# nrf54lm20a_enga_application register map
Vendor: Nordic Semiconductor; Series: nrf54l; File version: 1
CPU: CM33 r0p4, little endian, MPU, FPU, 3 interrupt priority bits, 270 interrupts, 4 SAU regions
Registers are 32-bit, read-write, reset 0x0 unless marked. A register's access mark holds for its fields unless they carry their own. Offsets are from the block's base; [hi:lo] are bit positions; lines under a group give offsets from that group; 'fields as' and 'values as' point back to an identical list.

## GLOBAL_CLOCK_NS — Clock management 0
Base 0x4010E000
Same registers: GLOBAL_CLOCK_S 0x5010E000
0x00 TASKS_XOSTART wo — Start crystal oscillator (HFXO)
  [0] TASKS_XOSTART
    1=Trigger task
0x04 TASKS_XOSTOP wo — Stop crystal oscillator (HFXO)
  [0] TASKS_XOSTOP
    1=Trigger task
0x08 TASKS_PLLSTART wo — Start PLL and keep it running, regardless of the automatic clock requests
  [0] TASKS_PLLSTART
    1=Trigger task
0x0C TASKS_PLLSTOP wo — Stop PLL
  [0] TASKS_PLLSTOP
    1=Trigger task
0x10 TASKS_LFCLKSTART wo — Start LFCLK source as selected in LFCLK.SRC
  [0] TASKS_LFCLKSTART
    1=Trigger task
0x14 TASKS_LFCLKSTOP wo — Stop LFCLK source
  [0] TASKS_LFCLKSTOP
    1=Trigger task
0x18 TASKS_CAL wo — Start calibration of LFRC oscillator
  [0] TASKS_CAL
    1=Trigger task
0x1C TASKS_XOTUNE wo — Request tuning for HFXO Request IDAC regulation for XOSC32M
  [0] TASKS_XOTUNE
    1=Trigger task
0x20 TASKS_XOTUNEABORT wo — Abort tuning for HFXO Abort IDAC regulation for XOSC32M. The latest IDAC code applied when ABORT is triggered will be used. Refer to DD: digip_1223
  [0] TASKS_XOTUNEABORT
    1=Trigger task
0x24 TASKS_XO24MSTART wo — Request HFXO to provide a crystal clock for PCLK24M
  [0] TASKS_XO24MSTART
    1=Trigger task
0x28 TASKS_XO24MSTOP wo — Stop request HFXO for PCLK24M. sWhen all requests for HFXO are stopped, HFXO will also stop.
  [0] TASKS_XO24MSTOP
    1=Trigger task
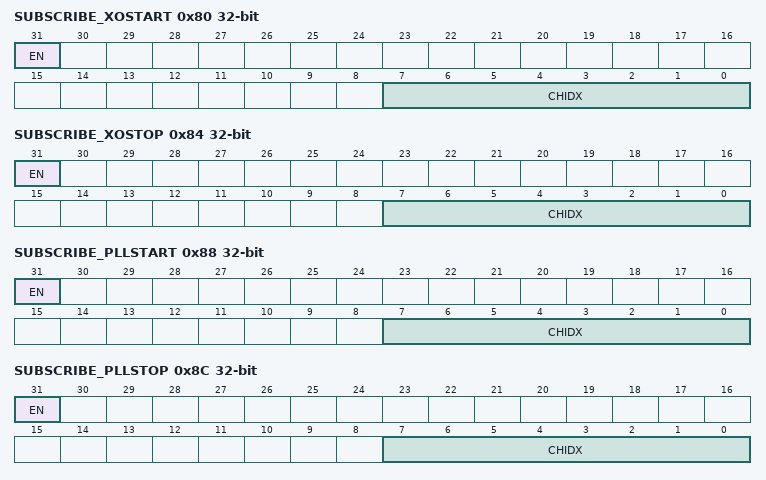
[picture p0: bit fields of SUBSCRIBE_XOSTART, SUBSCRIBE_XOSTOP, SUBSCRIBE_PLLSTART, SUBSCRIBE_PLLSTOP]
0x80 SUBSCRIBE_XOSTART — Subscribe configuration for task XOSTART
  [31] EN
    0=Disabled (Disable subscription); 1=Enabled (Enable subscription)
  [7:0] CHIDX — DPPI channel that task XOSTART will subscribe to
0x84 SUBSCRIBE_XOSTOP — Subscribe configuration for task XOSTOP
  [31] EN
    values as SUBSCRIBE_XOSTART.EN
  [7:0] CHIDX — DPPI channel that task XOSTOP will subscribe to
0x88 SUBSCRIBE_PLLSTART — Subscribe configuration for task PLLSTART
  [31] EN
    values as SUBSCRIBE_XOSTART.EN
  [7:0] CHIDX — DPPI channel that task PLLSTART will subscribe to
0x8C SUBSCRIBE_PLLSTOP — Subscribe configuration for task PLLSTOP
  [31] EN
    values as SUBSCRIBE_XOSTART.EN
  [7:0] CHIDX — DPPI channel that task PLLSTOP will subscribe to
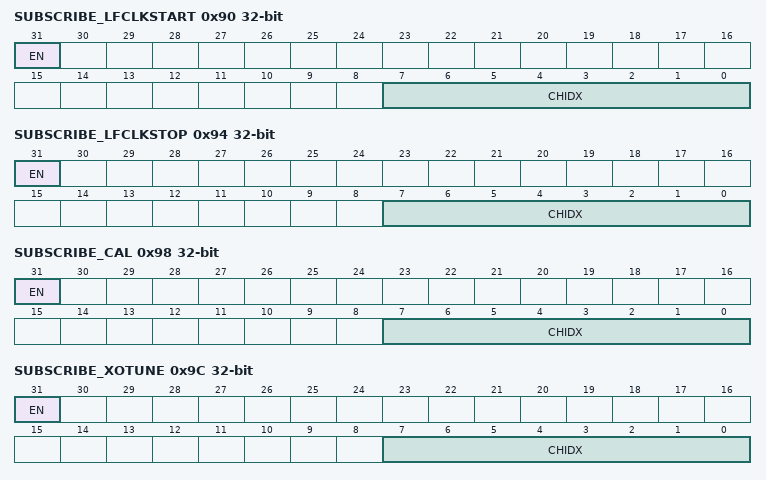
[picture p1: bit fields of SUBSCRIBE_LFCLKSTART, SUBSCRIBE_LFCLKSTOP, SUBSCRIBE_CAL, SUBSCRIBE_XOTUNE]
0x90 SUBSCRIBE_LFCLKSTART — Subscribe configuration for task LFCLKSTART
  [31] EN
    values as SUBSCRIBE_XOSTART.EN
  [7:0] CHIDX — DPPI channel that task LFCLKSTART will subscribe to
0x94 SUBSCRIBE_LFCLKSTOP — Subscribe configuration for task LFCLKSTOP
  [31] EN
    values as SUBSCRIBE_XOSTART.EN
  [7:0] CHIDX — DPPI channel that task LFCLKSTOP will subscribe to
0x98 SUBSCRIBE_CAL — Subscribe configuration for task CAL
  [31] EN
    values as SUBSCRIBE_XOSTART.EN
  [7:0] CHIDX — DPPI channel that task CAL will subscribe to
0x9C SUBSCRIBE_XOTUNE — Subscribe configuration for task XOTUNE
  [31] EN
    values as SUBSCRIBE_XOSTART.EN
  [7:0] CHIDX — DPPI channel that task XOTUNE will subscribe to
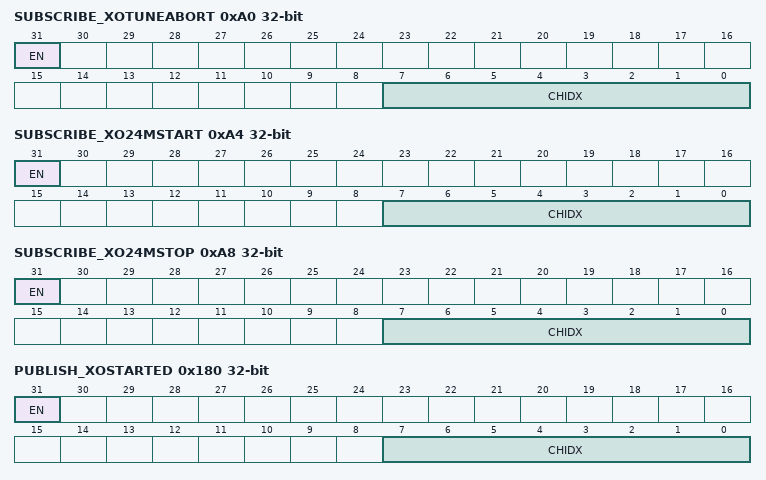
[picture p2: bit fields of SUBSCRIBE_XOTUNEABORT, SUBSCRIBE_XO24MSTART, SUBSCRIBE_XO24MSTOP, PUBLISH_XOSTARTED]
0xA0 SUBSCRIBE_XOTUNEABORT — Subscribe configuration for task XOTUNEABORT
  [31] EN
    values as SUBSCRIBE_XOSTART.EN
  [7:0] CHIDX — DPPI channel that task XOTUNEABORT will subscribe to
0xA4 SUBSCRIBE_XO24MSTART — Subscribe configuration for task XO24MSTART
  [31] EN
    values as SUBSCRIBE_XOSTART.EN
  [7:0] CHIDX — DPPI channel that task XO24MSTART will subscribe to
0xA8 SUBSCRIBE_XO24MSTOP — Subscribe configuration for task XO24MSTOP
  [31] EN
    values as SUBSCRIBE_XOSTART.EN
  [7:0] CHIDX — DPPI channel that task XO24MSTOP will subscribe to
0x100 EVENTS_XOSTARTED — Crystal oscillator has started
  [0] EVENTS_XOSTARTED
    0=NotGenerated (Event not generated); 1=Generated (Event generated)
0x104 EVENTS_PLLSTARTED — PLL started
  [0] EVENTS_PLLSTARTED
    values as EVENTS_XOSTARTED.EVENTS_XOSTARTED
0x108 EVENTS_LFCLKSTARTED — LFCLK source started
  [0] EVENTS_LFCLKSTARTED
    values as EVENTS_XOSTARTED.EVENTS_XOSTARTED
0x10C EVENTS_DONE — Calibration of LFRC oscillator complete event
  [0] EVENTS_DONE
    values as EVENTS_XOSTARTED.EVENTS_XOSTARTED
0x110 EVENTS_XOTUNED — HFXO tuning is done. XOTUNED is generated after TASKS_XOSTART or after TASKS_XOTUNE has completed IDAC regulation complete. XOSC32M quality is good (PKD = 011). Refer to DD: digip_1223
  [0] EVENTS_XOTUNED
    values as EVENTS_XOSTARTED.EVENTS_XOSTARTED
0x114 EVENTS_XOTUNEERROR — HFXO quality issue detected, XOTUNE is needed XOSC32M quality issue detected (PKD = 111 or 001). IDAC regulation needed. Refer to DD: digip_1223
  [0] EVENTS_XOTUNEERROR
    values as EVENTS_XOSTARTED.EVENTS_XOSTARTED
0x118 EVENTS_XOTUNEFAILED — HFXO tuning could not be completed IDAC regulation timed out. XOSC32M could not find a good IDAC code and does not have good quality (PKD = 111 or 001) Could be a crystal failure or wrong capacitor values. Can also be too short IDAC regulation time setting. Refer to DD: digip_1223
  [0] EVENTS_XOTUNEFAILED
    values as EVENTS_XOSTARTED.EVENTS_XOSTARTED
0x11C EVENTS_XO24MSTARTED — XO24M started
  [0] EVENTS_XO24MSTARTED
    values as EVENTS_XOSTARTED.EVENTS_XOSTARTED
0x180 PUBLISH_XOSTARTED — Publish configuration for event XOSTARTED
  [31] EN
    0=Disabled (Disable publishing); 1=Enabled (Enable publishing)
  [7:0] CHIDX — DPPI channel that event XOSTARTED will publish to
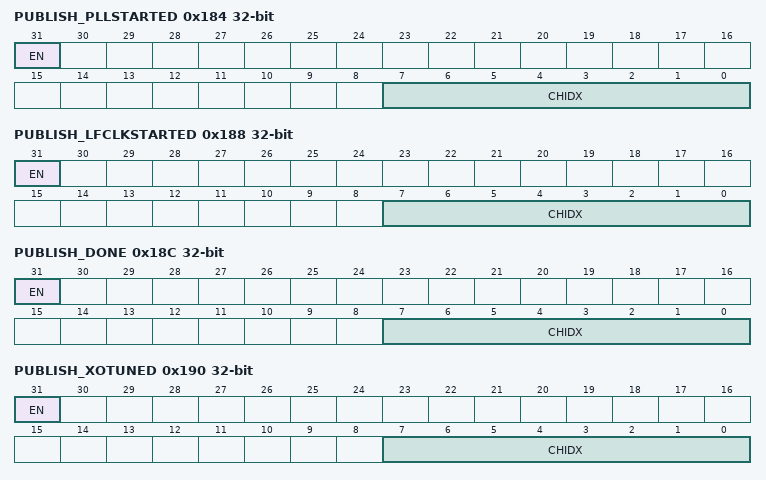
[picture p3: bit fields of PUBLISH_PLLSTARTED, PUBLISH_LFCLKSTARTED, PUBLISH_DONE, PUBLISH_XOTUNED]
0x184 PUBLISH_PLLSTARTED — Publish configuration for event PLLSTARTED
  [31] EN
    values as PUBLISH_XOSTARTED.EN
  [7:0] CHIDX — DPPI channel that event PLLSTARTED will publish to
0x188 PUBLISH_LFCLKSTARTED — Publish configuration for event LFCLKSTARTED
  [31] EN
    values as PUBLISH_XOSTARTED.EN
  [7:0] CHIDX — DPPI channel that event LFCLKSTARTED will publish to
0x18C PUBLISH_DONE — Publish configuration for event DONE
  [31] EN
    values as PUBLISH_XOSTARTED.EN
  [7:0] CHIDX — DPPI channel that event DONE will publish to
0x190 PUBLISH_XOTUNED — Publish configuration for event XOTUNED
  [31] EN
    values as PUBLISH_XOSTARTED.EN
  [7:0] CHIDX — DPPI channel that event XOTUNED will publish to
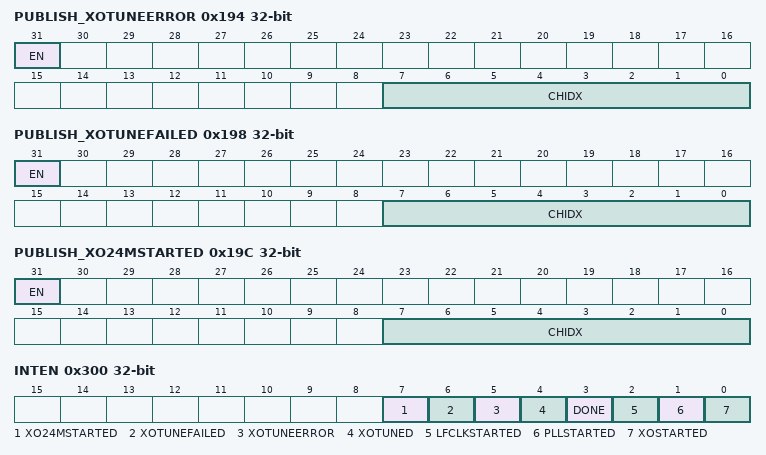
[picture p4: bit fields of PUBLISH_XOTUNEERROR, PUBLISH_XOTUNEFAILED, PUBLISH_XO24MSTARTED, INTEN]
0x194 PUBLISH_XOTUNEERROR — Publish configuration for event XOTUNEERROR
  [31] EN
    values as PUBLISH_XOSTARTED.EN
  [7:0] CHIDX — DPPI channel that event XOTUNEERROR will publish to
0x198 PUBLISH_XOTUNEFAILED — Publish configuration for event XOTUNEFAILED
  [31] EN
    values as PUBLISH_XOSTARTED.EN
  [7:0] CHIDX — DPPI channel that event XOTUNEFAILED will publish to
0x19C PUBLISH_XO24MSTARTED — Publish configuration for event XO24MSTARTED
  [31] EN
    values as PUBLISH_XOSTARTED.EN
  [7:0] CHIDX — DPPI channel that event XO24MSTARTED will publish to
0x300 INTEN — Enable or disable interrupt
  [all] fields
    0=Disabled; 1=Enabled
  [7] XO24MSTARTED — Enable or disable interrupt for event XO24MSTARTED
  [6] XOTUNEFAILED — Enable or disable interrupt for event XOTUNEFAILED
  [5] XOTUNEERROR — Enable or disable interrupt for event XOTUNEERROR
  [4] XOTUNED — Enable or disable interrupt for event XOTUNED
  [3] DONE — Enable or disable interrupt for event DONE
  [2] LFCLKSTARTED — Enable or disable interrupt for event LFCLKSTARTED
  [1] PLLSTARTED — Enable or disable interrupt for event PLLSTARTED
  [0] XOSTARTED — Enable or disable interrupt for event XOSTARTED
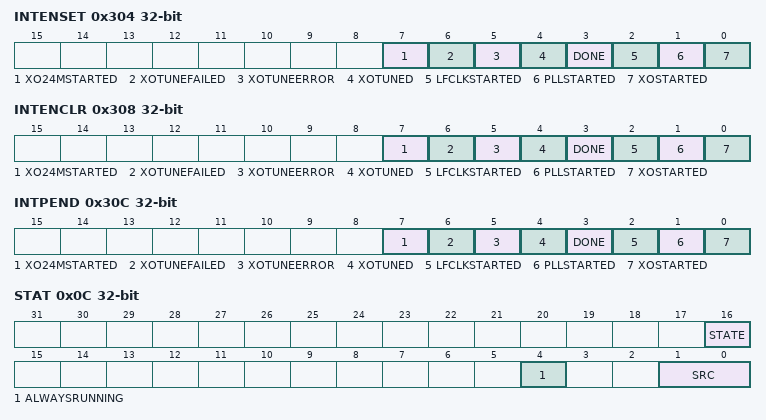
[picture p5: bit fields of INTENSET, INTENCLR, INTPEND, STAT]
0x304 INTENSET — Enable interrupt
  [all] fields
    on read: 0=Disabled (Read: Disabled); 1=Enabled (Read: Enabled) | on write: 1=Set (Enable)
  [7] XO24MSTARTED — Write '1' to enable interrupt for event XO24MSTARTED
  [6] XOTUNEFAILED — Write '1' to enable interrupt for event XOTUNEFAILED
  [5] XOTUNEERROR — Write '1' to enable interrupt for event XOTUNEERROR
  [4] XOTUNED — Write '1' to enable interrupt for event XOTUNED
  [3] DONE — Write '1' to enable interrupt for event DONE
  [2] LFCLKSTARTED — Write '1' to enable interrupt for event LFCLKSTARTED
  [1] PLLSTARTED — Write '1' to enable interrupt for event PLLSTARTED
  [0] XOSTARTED — Write '1' to enable interrupt for event XOSTARTED
0x308 INTENCLR — Disable interrupt
  [all] fields
    on read: 0=Disabled (Read: Disabled); 1=Enabled (Read: Enabled) | on write: 1=Clear (Disable)
  [7] XO24MSTARTED — Write '1' to disable interrupt for event XO24MSTARTED
  [6] XOTUNEFAILED — Write '1' to disable interrupt for event XOTUNEFAILED
  [5] XOTUNEERROR — Write '1' to disable interrupt for event XOTUNEERROR
  [4] XOTUNED — Write '1' to disable interrupt for event XOTUNED
  [3] DONE — Write '1' to disable interrupt for event DONE
  [2] LFCLKSTARTED — Write '1' to disable interrupt for event LFCLKSTARTED
  [1] PLLSTARTED — Write '1' to disable interrupt for event PLLSTARTED
  [0] XOSTARTED — Write '1' to disable interrupt for event XOSTARTED
0x30C INTPEND ro — Pending interrupts
  [all] fields
    on read: 0=NotPending (Read: Not pending); 1=Pending (Read: Pending)
  [7] XO24MSTARTED — Read pending status of interrupt for event XO24MSTARTED
  [6] XOTUNEFAILED — Read pending status of interrupt for event XOTUNEFAILED
  [5] XOTUNEERROR — Read pending status of interrupt for event XOTUNEERROR
  [4] XOTUNED — Read pending status of interrupt for event XOTUNED
  [3] DONE — Read pending status of interrupt for event DONE
  [2] LFCLKSTARTED — Read pending status of interrupt for event LFCLKSTARTED
  [1] PLLSTARTED — Read pending status of interrupt for event PLLSTARTED
  [0] XOSTARTED — Read pending status of interrupt for event XOSTARTED
0x400 XO group — Unspecified
  0x00 SRC reset 0x1 — Clock source for XO
    [1:0] SRC — Select which XO source is started by the XOSTART task
      0=HFINT (Reserved for future use, do not use); 1=HFXO (XOSTART task starts the high frequency crystal oscillator)
  0x04 ALWAYSRUN — Request clock to run independent of the automatic clock request system.
    [0] ALWAYSRUN — Ensure XO is always running
      0=Automatic (Use automatic control); 1=AlwaysRun (Ensure XO is always running)
  0x08 RUN ro — Indicates that XOSTART task was triggered
    [0] STATUS — XOSTART task triggered or not
      0=NotTriggered (Task not triggered); 1=Triggered (Task triggered)
  0x0C STAT ro — XO status
    [16] STATE — XO state (Running between START task and STOPPED event)
      0=NotRunning (XO is not running); 1=Running (XO is running)
    [4] ALWAYSRUNNING — ALWAYSRUN activated
      0=NotRunning (Automatic clock control enabled); 1=Running (XO is always running)
    [1:0] SRC — Which XO settings were selected when triggering START task
      0=HFINT (Reserved for future use, do not use); 1=HFXO
0x420 PLL group — Unspecified
  0x00 SRC — Clock source for PLL
    [1:0] SRC — Select which PLL source is started by the PLLSTART task
      0=HFINT (Reserved for future use, do not use)
  0x04 ALWAYSRUN — Request clock to run independent of the automatic clock request system.
    [0] ALWAYSRUN — Ensure PLL is always running
      0=Automatic (Use automatic control); 1=AlwaysRun (Ensure PLL is always running)
  0x08 RUN ro — Indicates that PLLSTART task was triggered
    [0] STATUS — PLLSTART task triggered or not
      values as XO.RUN.STATUS
  0x0C STAT ro — Which PLL settings were selected when triggering START task
    [16] STATE — PLL state (Running between START task and STOPPED event)
      0=NotRunning (PLL is not running); 1=Running (PLL is running)
    [4] ALWAYSRUNNING — ALWAYSRUN activated
      0=NotRunning (Automatic clock control enabled); 1=Running (PLL is always running)
0x440 LFCLK group — Unspecified
  0x00 SRC — Clock source for LFCLK
    [1:0] SRC — Select which LFCLK source is started by the LFCLKSTART task
      0=LFRC (32.768 kHz RC oscillator); 1=LFXO (32.768 kHz crystal oscillator); 2=LFSYNT (32.768 kHz synthesized from HFCLK)
  0x04 ALWAYSRUN — Request clock to run independent of the automatic clock request system.
    [0] ALWAYSRUN — Ensure clock is running
      0=Automatic (Use automatic clock control); 1=AlwaysRun (Ensure clock is running)
  0x08 RUN ro — Indicates that LFCLKSTART task was triggered
    [0] STATUS — LFCLKSTART task triggered or not
      values as XO.RUN.STATUS
  0x0C STAT ro — Copy of LFCLK.SRCCOPY register, set when LFCLKSTARTED event is triggered.
    [16] STATE — LFCLK state (Running between START task and STOPPED event)
      0=NotRunning (LFCLK not running); 1=Running (LFCLK running)
    [4] ALWAYSRUNNING — ALWAYSRUN activated
      0=NotRunning (Automatic clock control enabled); 1=Running (Oscillator is always running)
    [1:0] SRC — Value of LFCLK.SRCCOPY register when LFCLKSTARTED event was triggered
      values as LFCLK.SRC.SRC
  0x10 SRCCOPY — Copy of LFCLK.SRC register, set when LFCLKSTART task is triggered
    [1:0] SRC — Value of LFCLK.SRC register when LFCLKSTART task was triggered
      values as LFCLK.SRC.SRC
0x460 PLL24M group — Unspecified
  0x00 SRC — Clock source for PLL24M
    [1:0] SRC — Select which PLL24M source is started by the XO24MSTART task
      0=HFINT (Reserved for future use, do not use); 1=HFXO (XO24MSTART task starts the high frequency crystal oscillator)
  0x04 ALWAYSRUN — Request clock to run independent of the automatic clock request system.
    [0] ALWAYSRUN — Ensure PLL is always running
      0=Automatic (Use automatic control); 1=AlwaysRun (Ensure PLL24M is always running)
  0x08 RUN ro — Indicates that XO24MSTART task was triggered
    [0] STATUS — XO24MSTART task triggered or not
      values as XO.RUN.STATUS
  0x0C STAT ro — Which PLL settings were selected when triggering START task
    [16] STATE — PLL state (Running between START task and STOPPED event)
      0=NotRunning (PLL24M is not running); 1=Running (PLL24M is running)
    [4] ALWAYSRUNNING — ALWAYSRUN activated
      0=NotRunning (Automatic clock control enabled); 1=Running (PLL24M is always running)
